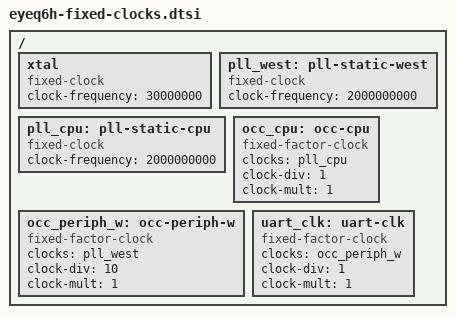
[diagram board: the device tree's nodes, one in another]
// SPDX-License-Identifier: (GPL-2.0-only OR BSD-2-Clause)
/*
 * Copyright 2023 Mobileye Vision Technologies Ltd.
 */

#include <dt-bindings/clock/mobileye,eyeq5-clk.h>

/ {
	xtal: xtal {
		compatible = "fixed-clock";
		#clock-cells = <0>;
		clock-frequency = <30000000>;
	};

	pll_west: pll-static-west {
		compatible = "fixed-clock";
		#clock-cells = <0>;
		clock-frequency = <2000000000>;
	};

	pll_cpu: pll-static-cpu {
		compatible = "fixed-clock";
		#clock-cells = <0>;
		clock-frequency = <2000000000>;
	};

	/* pll-cpu derivatives */
	occ_cpu: occ-cpu {
		compatible = "fixed-factor-clock";
		clocks = <&pll_cpu>;
		#clock-cells = <0>;
		clock-div = <1>;
		clock-mult = <1>;
	};

	/* pll-west derivatives */
	occ_periph_w: occ-periph-w {
		compatible = "fixed-factor-clock";
		clocks = <&pll_west>;
		#clock-cells = <0>;
		clock-div = <10>;
		clock-mult = <1>;
	};
	uart_clk: uart-clk {
		compatible = "fixed-factor-clock";
		clocks = <&occ_periph_w>;
		#clock-cells = <0>;
		clock-div = <1>;
		clock-mult = <1>;
	};

};
